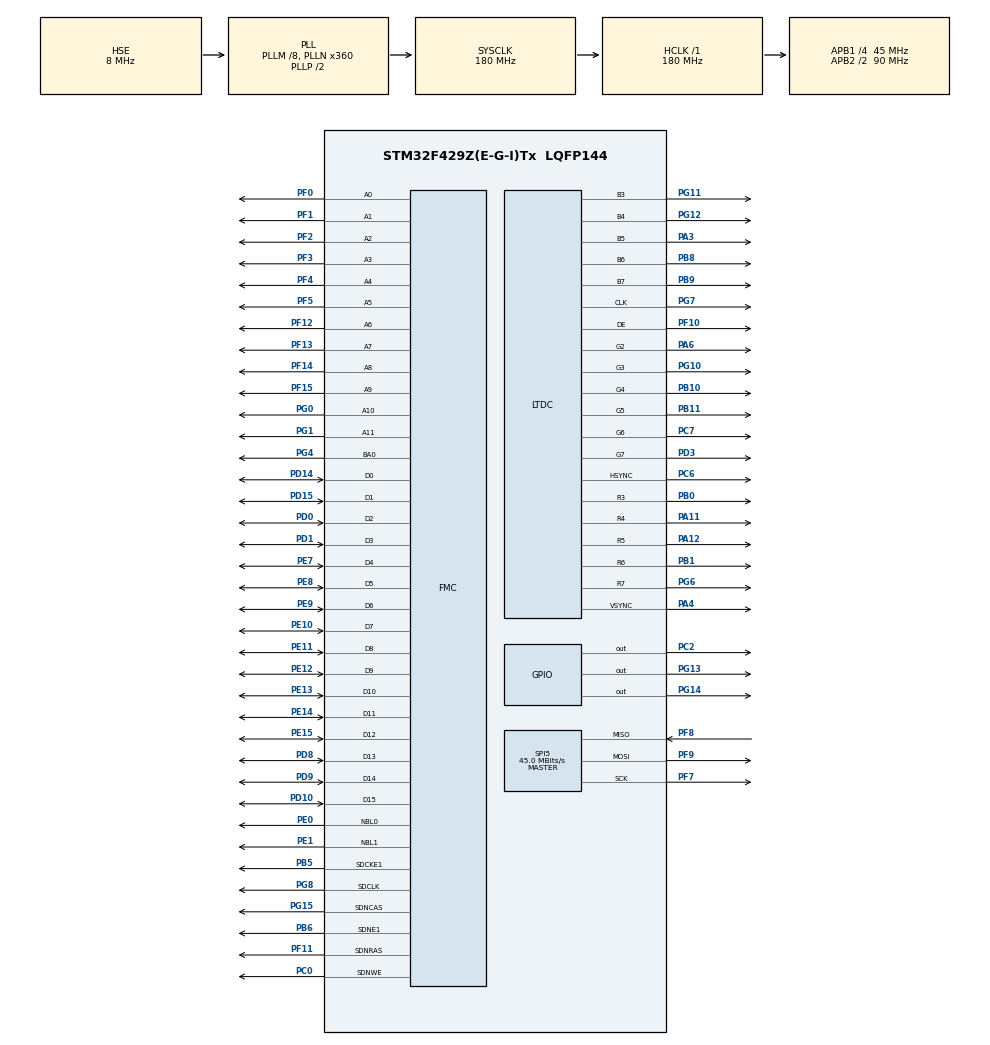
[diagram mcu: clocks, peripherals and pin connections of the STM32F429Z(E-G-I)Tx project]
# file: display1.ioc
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FMC.CASLatency1=FMC_SDRAM_CAS_LATENCY_3
FMC.ExitSelfRefreshDelay1=6
FMC.LoadToActiveDelay1=2
FMC.RCDDelay1=2
FMC.RPDelay1=2
FMC.RPDelay2=2
FMC.ReadPipeDelay1=FMC_SDRAM_RPIPE_DELAY_1
FMC.ReadPipeDelay2=FMC_SDRAM_RPIPE_DELAY_1
FMC.RowCycleDelay1=6
FMC.RowCycleDelay2=6
FMC.SDClockPeriod1=FMC_SDRAM_CLOCK_PERIOD_2
FMC.SDClockPeriod2=FMC_SDRAM_CLOCK_PERIOD_2
FMC.SelfRefreshTime1=4
FMC.WriteRecoveryTime1=2
LTDC.ActiveH=320
LTDC.ActiveW=240
LTDC.Alpha_L0=0
LTDC.Alpha_L1=0
LTDC.BlendingFactor1_L0=LTDC_BLENDING_FACTOR1_CA
LTDC.BlendingFactor1_L1=LTDC_BLENDING_FACTOR1_CA
LTDC.BlendingFactor2_L0=LTDC_BLENDING_FACTOR2_CA
LTDC.BlendingFactor2_L1=LTDC_BLENDING_FACTOR2_CA
LTDC.HBP=20
LTDC.HFP=10
LTDC.HSync=10
LTDC.PixelFormat_L0_not888=LTDC_PIXEL_FORMAT_RGB565
LTDC.PixelFormat_L1_not888=LTDC_PIXEL_FORMAT_RGB565
LTDC.VFP=4
LTDC.VSync=2
LTDC.WindowX1_L0=240
LTDC.WindowX1_L1=240
LTDC.WindowY1_L0=320
LTDC.WindowY1_L1=320
Mcu.Family=STM32F4
Mcu.Name=STM32F429Z(E-G-I)Tx
Mcu.Package=LQFP144
NVIC.PriorityGroup=NVIC_PRIORITYGROUP_4
PA11.GPIO_Speed=GPIO_SPEED_FREQ_VERY_HIGH
PA11.Mode=RGB565
PA11.Signal=LTDC_R4
PA12.GPIO_Speed=GPIO_SPEED_FREQ_VERY_HIGH
PA12.Mode=RGB565
PA12.Signal=LTDC_R5
PA3.GPIO_Speed=GPIO_SPEED_FREQ_VERY_HIGH
PA3.Mode=RGB565
PA3.Signal=LTDC_B5
PA4.GPIO_Speed=GPIO_SPEED_FREQ_VERY_HIGH
PA4.Mode=RGB565
PA4.Signal=LTDC_VSYNC
PA6.GPIO_Speed=GPIO_SPEED_FREQ_VERY_HIGH
PA6.Mode=RGB565
PA6.Signal=LTDC_G2
PB0.GPIO_Speed=GPIO_SPEED_FREQ_VERY_HIGH
PB0.Mode=RGB565
PB0.Signal=LTDC_R3
PB1.GPIO_Speed=GPIO_SPEED_FREQ_VERY_HIGH
PB1.Mode=RGB565
PB1.Signal=LTDC_R6
PB10.GPIO_Speed=GPIO_SPEED_FREQ_VERY_HIGH
PB10.Mode=RGB565
PB10.Signal=LTDC_G4
PB11.GPIO_Speed=GPIO_SPEED_FREQ_VERY_HIGH
PB11.Mode=RGB565
PB11.Signal=LTDC_G5
PB5.Mode=SdramChipSelect2_1
PB5.Signal=FMC_SDCKE1
PB6.Mode=SdramChipSelect2_1
PB6.Signal=FMC_SDNE1
PB8.GPIO_Speed=GPIO_SPEED_FREQ_VERY_HIGH
PB8.Mode=RGB565
PB8.Signal=LTDC_B6
PB9.GPIO_Speed=GPIO_SPEED_FREQ_VERY_HIGH
PB9.Mode=RGB565
PB9.Signal=LTDC_B7
PC0.Signal=FMC_SDNWE
PC10.GPIO_Speed=GPIO_SPEED_FREQ_HIGH
PC10.Signal=LTDC_R2
PC2.GPIO_Speed=GPIO_SPEED_FREQ_HIGH
PC2.Signal=GPIO_Output
PC6.GPIO_Speed=GPIO_SPEED_FREQ_VERY_HIGH
PC6.Mode=RGB565
PC6.Signal=LTDC_HSYNC
PC7.GPIO_Speed=GPIO_SPEED_FREQ_VERY_HIGH
PC7.Mode=RGB565
PC7.Signal=LTDC_G6
PD0.Signal=FMC_D2_DA2
PD1.Signal=FMC_D3_DA3
PD10.Signal=FMC_D15_DA15
PD14.Signal=FMC_D0_DA0
PD15.Signal=FMC_D1_DA1
PD3.GPIO_Speed=GPIO_SPEED_FREQ_VERY_HIGH
PD3.Mode=RGB565
PD3.Signal=LTDC_G7
PD8.Signal=FMC_D13_DA13
PD9.Signal=FMC_D14_DA14
PE0.Signal=FMC_NBL0
PE1.Signal=FMC_NBL1
PE10.Signal=FMC_D7_DA7
PE11.Signal=FMC_D8_DA8
PE12.Signal=FMC_D9_DA9
PE13.Signal=FMC_D10_DA10
PE14.Signal=FMC_D11_DA11
PE15.Signal=FMC_D12_DA12
PE7.Signal=FMC_D4_DA4
PE8.Signal=FMC_D5_DA5
PE9.Signal=FMC_D6_DA6
PF0.Signal=FMC_A0
PF1.Signal=FMC_A1
PF10.GPIO_Speed=GPIO_SPEED_FREQ_VERY_HIGH
PF10.Mode=RGB565
PF10.Signal=LTDC_DE
PF11.Signal=FMC_SDNRAS
PF12.Signal=FMC_A6
PF13.Signal=FMC_A7
PF14.Signal=FMC_A8
PF15.Signal=FMC_A9
PF2.Signal=FMC_A2
PF3.Signal=FMC_A3
PF4.Signal=FMC_A4
PF5.Signal=FMC_A5
PF7.Mode=Full_Duplex_Master
PF7.Signal=SPI5_SCK
PF8.Mode=Full_Duplex_Master
PF8.Signal=SPI5_MISO
PF9.Mode=Full_Duplex_Master
PF9.Signal=SPI5_MOSI
PG0.Signal=FMC_A10
PG1.Signal=FMC_A11
PG10.GPIO_Speed=GPIO_SPEED_FREQ_VERY_HIGH
PG10.Mode=RGB565
PG10.Signal=LTDC_G3
PG11.GPIO_Speed=GPIO_SPEED_FREQ_VERY_HIGH
PG11.Mode=RGB565
PG11.Signal=LTDC_B3
PG12.GPIO_Speed=GPIO_SPEED_FREQ_VERY_HIGH
PG12.Mode=RGB565
PG12.Signal=LTDC_B4
PG13.Signal=GPIO_Output
PG14.Signal=GPIO_Output
PG15.Signal=FMC_SDNCAS
PG4.Signal=FMC_A14_BA0
PG5.Signal=FMC_A15_BA1
PG6.GPIO_Speed=GPIO_SPEED_FREQ_VERY_HIGH
PG6.Mode=RGB565
PG6.Signal=LTDC_R7
PG7.GPIO_Speed=GPIO_SPEED_FREQ_VERY_HIGH
PG7.Mode=RGB565
PG7.Signal=LTDC_CLK
PG8.Signal=FMC_SDCLK
PH0/OSC_IN.Mode=HSE-External-Oscillator
PH0/OSC_IN.Signal=RCC_OSC_IN
PH1/OSC_OUT.Mode=HSE-External-Oscillator
PH1/OSC_OUT.Signal=RCC_OSC_OUT
ProjectManager.HeapSize=0x200
ProjectManager.StackSize=0x400
ProjectManager.TargetToolchain=MDK-ARM V5
RCC.48MHZClocksFreq_Value=45000000
RCC.AHBFreq_Value=180000000
RCC.APB1CLKDivider=RCC_HCLK_DIV4
RCC.APB1Freq_Value=45000000
RCC.APB1TimFreq_Value=90000000
RCC.APB2CLKDivider=RCC_HCLK_DIV2
RCC.APB2Freq_Value=90000000
RCC.APB2TimFreq_Value=180000000
RCC.CortexFreq_Value=180000000
RCC.HCLKFreq_Value=180000000
RCC.HSE_VALUE=8000000
RCC.HSI_VALUE=16000000
RCC.LSE_VALUE=32768
RCC.PLLM=8
RCC.PLLN=360
RCC.PLLQ=8
RCC.PLLSAIDivR=RCC_PLLSAIDIVR_4
RCC.PLLSAIN=192
RCC.PLLSAIR=3
RCC.PLLSourceVirtual=RCC_PLLSOURCE_HSE
RCC.SYSCLKFreq_VALUE=180000000
RCC.SYSCLKSource=RCC_SYSCLKSOURCE_PLLCLK
RCC.VCOOutputFreq_Value=360000000
SH.FMC_A0.0=FMC_A0,12b-sda1
SH.FMC_A1.0=FMC_A1,12b-sda1
SH.FMC_A10.0=FMC_A10,12b-sda1
SH.FMC_A11.0=FMC_A11,12b-sda1
SH.FMC_A14_BA0.0=FMC_BA0,TwoSdramBanks1
SH.FMC_A15_BA1.0=FMC_BA1
SH.FMC_A2.0=FMC_A2,12b-sda1
SH.FMC_A3.0=FMC_A3,12b-sda1
SH.FMC_A4.0=FMC_A4,12b-sda1
SH.FMC_A5.0=FMC_A5,12b-sda1
SH.FMC_A6.0=FMC_A6,12b-sda1
SH.FMC_A7.0=FMC_A7,12b-sda1
SH.FMC_A8.0=FMC_A8,12b-sda1
SH.FMC_A9.0=FMC_A9,12b-sda1
SH.FMC_D0_DA0.0=FMC_D0,sd-16b-d1
SH.FMC_D10_DA10.0=FMC_D10,sd-16b-d1
SH.FMC_D11_DA11.0=FMC_D11,sd-16b-d1
SH.FMC_D12_DA12.0=FMC_D12,sd-16b-d1
SH.FMC_D13_DA13.0=FMC_D13,sd-16b-d1
SH.FMC_D14_DA14.0=FMC_D14,sd-16b-d1
SH.FMC_D15_DA15.0=FMC_D15,sd-16b-d1
SH.FMC_D1_DA1.0=FMC_D1,sd-16b-d1
SH.FMC_D2_DA2.0=FMC_D2,sd-16b-d1
SH.FMC_D3_DA3.0=FMC_D3,sd-16b-d1
SH.FMC_D4_DA4.0=FMC_D4,sd-16b-d1
SH.FMC_D5_DA5.0=FMC_D5,sd-16b-d1
SH.FMC_D6_DA6.0=FMC_D6,sd-16b-d1
SH.FMC_D7_DA7.0=FMC_D7,sd-16b-d1
SH.FMC_D8_DA8.0=FMC_D8,sd-16b-d1
SH.FMC_D9_DA9.0=FMC_D9,sd-16b-d1
SH.FMC_NBL0.0=FMC_NBL0,Sd2ByteEnable1
SH.FMC_NBL1.0=FMC_NBL1,Sd2ByteEnable1
SH.FMC_SDCLK.0=FMC_SDCLK,12b-sda1
SH.FMC_SDNCAS.0=FMC_SDNCAS,12b-sda1
SH.FMC_SDNRAS.0=FMC_SDNRAS,12b-sda1
SH.FMC_SDNWE.0=FMC_SDNWE,12b-sda1
SPI5.BaudRatePrescaler=SPI_BAUDRATEPRESCALER_2
SPI5.CalculateBaudRate=45.0 MBits/s
SPI5.Mode=SPI_MODE_MASTER
VP_RNG_VS_RNG.Mode=RNG_Activate
board=display1

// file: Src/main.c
/**
  ******************************************************************************
  * File Name          : main.c
  * Description        : Main program body
  ******************************************************************************
  *
  * COPYRIGHT(c) 2017 STMicroelectronics
  *
  * Redistribution and use in source and binary forms, with or without modification,
  * are permitted provided that the following conditions are met:
  *   1. Redistributions of source code must retain the above copyright notice,
  *      this list of conditions and the following disclaimer.
  *   2. Redistributions in binary form must reproduce the above copyright notice,
  *      this list of conditions and the following disclaimer in the documentation
  *      and/or other materials provided with the distribution.
  *   3. Neither the name of STMicroelectronics nor the names of its contributors
  *      may be used to endorse or promote products derived from this software
  *      without specific prior written permission.
  *
  * THIS SOFTWARE IS PROVIDED BY THE COPYRIGHT HOLDERS AND CONTRIBUTORS "AS IS"
  * AND ANY EXPRESS OR IMPLIED WARRANTIES, INCLUDING, BUT NOT LIMITED TO, THE
  * IMPLIED WARRANTIES OF MERCHANTABILITY AND FITNESS FOR A PARTICULAR PURPOSE ARE
  * DISCLAIMED. IN NO EVENT SHALL THE COPYRIGHT HOLDER OR CONTRIBUTORS BE LIABLE
  * FOR ANY DIRECT, INDIRECT, INCIDENTAL, SPECIAL, EXEMPLARY, OR CONSEQUENTIAL
  * DAMAGES (INCLUDING, BUT NOT LIMITED TO, PROCUREMENT OF SUBSTITUTE GOODS OR
  * SERVICES; LOSS OF USE, DATA, OR PROFITS; OR BUSINESS INTERRUPTION) HOWEVER
  * CAUSED AND ON ANY THEORY OF LIABILITY, WHETHER IN CONTRACT, STRICT LIABILITY,
  * OR TORT (INCLUDING NEGLIGENCE OR OTHERWISE) ARISING IN ANY WAY OUT OF THE USE
  * OF THIS SOFTWARE, EVEN IF ADVISED OF THE POSSIBILITY OF SUCH DAMAGE.
  *
  ******************************************************************************
  */
#include "main.h"
#include "stm32f4xx_hal.h"

/* USER CODE BEGIN Includes */
#include "ili9341.h"
#include "lcd.h"
#include "image.h"
/* USER CODE END Includes */

LTDC_HandleTypeDef hltdc;

RNG_HandleTypeDef hrng;

SPI_HandleTypeDef hspi5;

SDRAM_HandleTypeDef hsdram1;

/* USER CODE BEGIN PV */
/* Private variables ---------------------------------------------------------*/

/* USER CODE END PV */

void SystemClock_Config(void);
void Error_Handler(void);
static void MX_GPIO_Init(void);
static void MX_LTDC_Init(void);
static void MX_RNG_Init(void);
static void MX_SPI5_Init(void);
static void MX_FMC_Init(void);

/* USER CODE BEGIN PFP */
/* Private function prototypes -----------------------------------------------*/

/* USER CODE END PFP */

/* USER CODE BEGIN 0 */
volatile uint16_t RGB565_320x240[38400] = {0xffff};
volatile uint16_t RGB565_320x240_2[38400] = {0x0000};

/**
  * @brief  Reload Event callback.
  * @param  hltdc: pointer to a LTDC_HandleTypeDef structure that contains
  *                the configuration information for the LTDC.
  * @retval None
  */
void HAL_LTDC_ReloadEventCallback(LTDC_HandleTypeDef *hltdc)
{
//  ReloadFlag = 1;
}
/* USER CODE END 0 */

int main(void)
{

  /* MCU Configuration----------------------------------------------------------*/

  /* Reset of all peripherals, Initializes the Flash interface and the Systick. */
  HAL_Init();

  /* Configure the system clock */
  SystemClock_Config();

  /* Initialize all configured peripherals */
  MX_GPIO_Init();
	MX_SPI5_Init();
	ili9341_Init();
  MX_LTDC_Init();
  MX_RNG_Init();
  MX_FMC_Init();

  /* USER CODE BEGIN 2 */

//	ram_init();
//	HAL_LTDC_SetAddress(&hltdc,(uint32_t)&RGB565_320x240,0);
//	HAL_Delay(500);
//	TFT_FillScreen((uint16_t)0x07E0);
//	HAL_Delay(5000);
  /* USER CODE END 2 */

  /* Infinite loop */
  while (1)
  {

  }

}

/** System Clock Configuration
*/
void SystemClock_Config(void)
{

  RCC_OscInitTypeDef RCC_OscInitStruct;
  RCC_ClkInitTypeDef RCC_ClkInitStruct;
  RCC_PeriphCLKInitTypeDef PeriphClkInitStruct;

    /**Configure the main internal regulator output voltage
    */
  __HAL_RCC_PWR_CLK_ENABLE();

  __HAL_PWR_VOLTAGESCALING_CONFIG(PWR_REGULATOR_VOLTAGE_SCALE1);

    /**Initializes the CPU, AHB and APB busses clocks
    */
  RCC_OscInitStruct.OscillatorType = RCC_OSCILLATORTYPE_HSE;
  RCC_OscInitStruct.HSEState = RCC_HSE_ON;
  RCC_OscInitStruct.PLL.PLLState = RCC_PLL_ON;
  RCC_OscInitStruct.PLL.PLLSource = RCC_PLLSOURCE_HSE;
  RCC_OscInitStruct.PLL.PLLM = 8;
  RCC_OscInitStruct.PLL.PLLN = 360;
  RCC_OscInitStruct.PLL.PLLP = RCC_PLLP_DIV2;
  RCC_OscInitStruct.PLL.PLLQ = 8;
  if (HAL_RCC_OscConfig(&RCC_OscInitStruct) != HAL_OK)
  {
    Error_Handler();
  }

    /**Activate the Over-Drive mode
    */
  if (HAL_PWREx_EnableOverDrive() != HAL_OK)
  {
    Error_Handler();
  }

    /**Initializes the CPU, AHB and APB busses clocks
    */
  RCC_ClkInitStruct.ClockType = RCC_CLOCKTYPE_HCLK|RCC_CLOCKTYPE_SYSCLK
                              |RCC_CLOCKTYPE_PCLK1|RCC_CLOCKTYPE_PCLK2;
  RCC_ClkInitStruct.SYSCLKSource = RCC_SYSCLKSOURCE_PLLCLK;
  RCC_ClkInitStruct.AHBCLKDivider = RCC_SYSCLK_DIV1;
  RCC_ClkInitStruct.APB1CLKDivider = RCC_HCLK_DIV4;
  RCC_ClkInitStruct.APB2CLKDivider = RCC_HCLK_DIV2;

  if (HAL_RCC_ClockConfig(&RCC_ClkInitStruct, FLASH_LATENCY_5) != HAL_OK)
  {
    Error_Handler();
  }

  PeriphClkInitStruct.PeriphClockSelection = RCC_PERIPHCLK_LTDC;
  PeriphClkInitStruct.PLLSAI.PLLSAIN = 192;
  PeriphClkInitStruct.PLLSAI.PLLSAIR = 4;
  PeriphClkInitStruct.PLLSAIDivR = RCC_PLLSAIDIVR_8;
  if (HAL_RCCEx_PeriphCLKConfig(&PeriphClkInitStruct) != HAL_OK)
  {
    Error_Handler();
  }

    /**Configure the Systick interrupt time
    */
  HAL_SYSTICK_Config(HAL_RCC_GetHCLKFreq()/1000);

    /**Configure the Systick
    */
  HAL_SYSTICK_CLKSourceConfig(SYSTICK_CLKSOURCE_HCLK);

  /* SysTick_IRQn interrupt configuration */
  HAL_NVIC_SetPriority(SysTick_IRQn, 0, 0);
}

/* LTDC init function */
static void MX_LTDC_Init(void)
{

  LTDC_LayerCfgTypeDef pLayerCfg;
  LTDC_LayerCfgTypeDef pLayerCfg1;

  hltdc.Instance = LTDC;
  hltdc.Init.HSPolarity = LTDC_HSPOLARITY_AL;
  hltdc.Init.VSPolarity = LTDC_VSPOLARITY_AL;
  hltdc.Init.DEPolarity = LTDC_DEPOLARITY_AL;
  hltdc.Init.PCPolarity = LTDC_PCPOLARITY_IPC;
  hltdc.Init.HorizontalSync = 9;
  hltdc.Init.VerticalSync = 1;
  hltdc.Init.AccumulatedHBP = 29;
  hltdc.Init.AccumulatedVBP = 3;
  hltdc.Init.AccumulatedActiveW = 269;
  hltdc.Init.AccumulatedActiveH = 323;
  hltdc.Init.TotalWidth = 279;
  hltdc.Init.TotalHeigh = 327;
  hltdc.Init.Backcolor.Blue = 0;
  hltdc.Init.Backcolor.Green = 0;
  hltdc.Init.Backcolor.Red = 0;
  if (HAL_LTDC_Init(&hltdc) != HAL_OK)
  {
    Error_Handler();
  }

  pLayerCfg.WindowX0 = 0;
  pLayerCfg.WindowX1 = 240;
  pLayerCfg.WindowY0 = 160;
  pLayerCfg.WindowY1 = 320;
  pLayerCfg.PixelFormat = LTDC_PIXEL_FORMAT_RGB565;
  pLayerCfg.Alpha = 255;
  pLayerCfg.Alpha0 = 0;
  pLayerCfg.BlendingFactor1 = LTDC_BLENDING_FACTOR1_PAxCA;
  pLayerCfg.BlendingFactor2 = LTDC_BLENDING_FACTOR1_PAxCA;
  pLayerCfg.FBStartAdress = (uint32_t)&RGB565_320x240;
  pLayerCfg.ImageWidth = 0;
  pLayerCfg.ImageHeight = 0;
  pLayerCfg.Backcolor.Blue = 0;
  pLayerCfg.Backcolor.Green = 0;
  pLayerCfg.Backcolor.Red = 0;
  if (HAL_LTDC_ConfigLayer(&hltdc, &pLayerCfg, 0) != HAL_OK)
  {
    Error_Handler();
  }

  pLayerCfg1.WindowX0 = 10;
  pLayerCfg1.WindowX1 = 240;
  pLayerCfg1.WindowY0 = 160;
  pLayerCfg1.WindowY1 = 320;
  pLayerCfg1.PixelFormat = LTDC_PIXEL_FORMAT_RGB565;
  pLayerCfg1.Alpha = 255;
  pLayerCfg1.Alpha0 = 0;
  pLayerCfg1.BlendingFactor1 = LTDC_BLENDING_FACTOR1_PAxCA;
  pLayerCfg1.BlendingFactor2 = LTDC_BLENDING_FACTOR1_PAxCA;
  pLayerCfg1.FBStartAdress = (uint32_t)&ST_LOGO_1;
  pLayerCfg1.ImageWidth = 0;
  pLayerCfg1.ImageHeight = 0;
  pLayerCfg1.Backcolor.Blue = 0;
  pLayerCfg1.Backcolor.Green = 0;
  pLayerCfg1.Backcolor.Red = 0;
  if (HAL_LTDC_ConfigLayer(&hltdc, &pLayerCfg1, 1) != HAL_OK)
  {
    Error_Handler();
  }

}

/* RNG init function */
static void MX_RNG_Init(void)
{

  hrng.Instance = RNG;
  if (HAL_RNG_Init(&hrng) != HAL_OK)
  {
    Error_Handler();
  }

}

/* SPI5 init function */
static void MX_SPI5_Init(void)
{

  hspi5.Instance = SPI5;
  hspi5.Init.Mode = SPI_MODE_MASTER;
  hspi5.Init.Direction = SPI_DIRECTION_2LINES;
  hspi5.Init.DataSize = SPI_DATASIZE_8BIT;
  hspi5.Init.CLKPolarity = SPI_POLARITY_LOW;
  hspi5.Init.CLKPhase = SPI_PHASE_1EDGE;
  hspi5.Init.NSS = SPI_NSS_SOFT;
  hspi5.Init.BaudRatePrescaler = SPI_BAUDRATEPRESCALER_2;
  hspi5.Init.FirstBit = SPI_FIRSTBIT_MSB;
  hspi5.Init.TIMode = SPI_TIMODE_DISABLE;
  hspi5.Init.CRCCalculation = SPI_CRCCALCULATION_DISABLE;
  hspi5.Init.CRCPolynomial = 10;
  if (HAL_SPI_Init(&hspi5) != HAL_OK)
  {
    Error_Handler();
  }

}
/* FMC initialization function */
static void MX_FMC_Init(void)
{
  FMC_SDRAM_TimingTypeDef SdramTiming;

  /** Perform the SDRAM1 memory initialization sequence
  */
  hsdram1.Instance = FMC_SDRAM_DEVICE;
  /* hsdram1.Init */
  hsdram1.Init.SDBank = FMC_SDRAM_BANK2;
  hsdram1.Init.ColumnBitsNumber = FMC_SDRAM_COLUMN_BITS_NUM_8;
  hsdram1.Init.RowBitsNumber = FMC_SDRAM_ROW_BITS_NUM_12;
  hsdram1.Init.MemoryDataWidth = FMC_SDRAM_MEM_BUS_WIDTH_16;
  hsdram1.Init.InternalBankNumber = FMC_SDRAM_INTERN_BANKS_NUM_4;
  hsdram1.Init.CASLatency = FMC_SDRAM_CAS_LATENCY_3;
  hsdram1.Init.WriteProtection = FMC_SDRAM_WRITE_PROTECTION_DISABLE;
  hsdram1.Init.SDClockPeriod = FMC_SDRAM_CLOCK_PERIOD_2;
  hsdram1.Init.ReadBurst = FMC_SDRAM_RBURST_DISABLE;
  hsdram1.Init.ReadPipeDelay = FMC_SDRAM_RPIPE_DELAY_1;
  /* SdramTiming */
  SdramTiming.LoadToActiveDelay = 2;
  SdramTiming.ExitSelfRefreshDelay = 7;
  SdramTiming.SelfRefreshTime = 4;
  SdramTiming.RowCycleDelay = 7;
  SdramTiming.WriteRecoveryTime = 2;
  SdramTiming.RPDelay = 2;
  SdramTiming.RCDDelay = 2;

  if (HAL_SDRAM_Init(&hsdram1, &SdramTiming) != HAL_OK)
  {
    Error_Handler();
  }

}

/** Configure pins as
        * Analog
        * Input
        * Output
        * EVENT_OUT
        * EXTI
*/
static void MX_GPIO_Init(void)
{

  GPIO_InitTypeDef GPIO_InitStruct;

  /* GPIO Ports Clock Enable */
  __HAL_RCC_GPIOF_CLK_ENABLE();
  __HAL_RCC_GPIOH_CLK_ENABLE();
  __HAL_RCC_GPIOC_CLK_ENABLE();
  __HAL_RCC_GPIOA_CLK_ENABLE();
  __HAL_RCC_GPIOB_CLK_ENABLE();
  __HAL_RCC_GPIOG_CLK_ENABLE();
  __HAL_RCC_GPIOE_CLK_ENABLE();
  __HAL_RCC_GPIOD_CLK_ENABLE();

  /*Configure GPIO pin Output Level */
  HAL_GPIO_WritePin(GPIOC, GPIO_PIN_2, GPIO_PIN_RESET);

  /*Configure GPIO pin Output Level */
  HAL_GPIO_WritePin(GPIOG, GPIO_PIN_13|GPIO_PIN_14, GPIO_PIN_RESET);

  /*Configure GPIO pin : PC2 */
  GPIO_InitStruct.Pin = GPIO_PIN_2;
  GPIO_InitStruct.Mode = GPIO_MODE_OUTPUT_PP;
  GPIO_InitStruct.Pull = GPIO_NOPULL;
  GPIO_InitStruct.Speed = GPIO_SPEED_FREQ_HIGH;
  HAL_GPIO_Init(GPIOC, &GPIO_InitStruct);

  /*Configure GPIO pins : PG13 PG14 */
  GPIO_InitStruct.Pin = GPIO_PIN_13|GPIO_PIN_14;
  GPIO_InitStruct.Mode = GPIO_MODE_OUTPUT_PP;
  GPIO_InitStruct.Pull = GPIO_NOPULL;
  GPIO_InitStruct.Speed = GPIO_SPEED_FREQ_LOW;
  HAL_GPIO_Init(GPIOG, &GPIO_InitStruct);

}

void Error_Handler(void)
{
  while(1)
  {
  }
}

/************************ (C) COPYRIGHT STMicroelectronics *****END OF FILE****/
